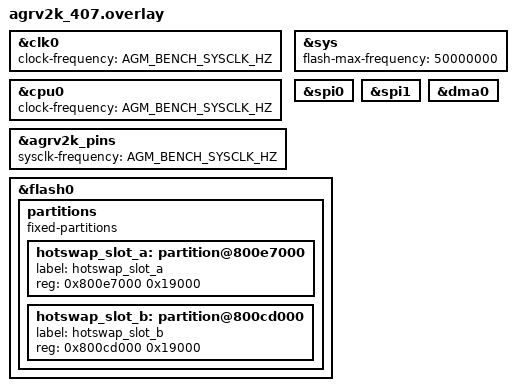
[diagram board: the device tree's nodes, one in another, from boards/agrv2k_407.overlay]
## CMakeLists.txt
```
# SPDX-License-Identifier: Apache-2.0
cmake_minimum_required(VERSION 3.20.0)

find_package(Zephyr REQUIRED HINTS $ENV{ZEPHYR_BASE})
project(fcb_hotswap)

target_sources(app PRIVATE src/main.c src/slot.c)
```

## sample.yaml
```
# SPDX-License-Identifier: Apache-2.0
sample:
  name: fcb_hotswap
  description: |
    Runtime (hot) fabric reload: validate a spare bitstream in FLASH, move the
    CPU onto the on-die HSI clock, run the FCB DEACTIVATE/AUTO/ACTIVATE
    sequence, hand the clock tree to the new fabric and re-assert the pin
    routes — all without a reboot. The SPI NOR RDID probe changes with the
    fabric while k_uptime keeps counting, which is the evidence. Requires two
    same-class bitstreams in FLASH (see README.md).
tests:
  sample.fcb_hotswap.agm_agrv2k_407:
    build_only: true
    platform_allow:
      - agrv2k_407
    integration_platforms:
      - agrv2k_407
    tags:
      - ci_build
      - hal_ag32
```

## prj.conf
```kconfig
# SPDX-License-Identifier: Apache-2.0
CONFIG_SERIAL=y
CONFIG_UART_CONSOLE=y
CONFIG_PRINTK=y
CONFIG_STDOUT_CONSOLE=y
CONFIG_XIP=y

# The fabric-change evidence is a SPI NOR RDID probe: which controller reaches
# the flash, and whether the engine sees MISO at all, is a property of the
# bitstream that is live. Same SPI/DMA set as samples/spi_flash_id.
CONFIG_SPI=y
CONFIG_DMA=y

# The sample re-asserts the console/SPI pin routes after the swap (the new
# bitstream owns AFSEL at ACTIVATE), so pinctrl must be on.
CONFIG_PINCTRL=y

# CPU clock-frequency is a devicetree literal (kernel tick) — nothing to set
# here. No CONFIG_REBOOT: this sample's whole point is *not* rebooting.
```

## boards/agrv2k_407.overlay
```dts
/* SPDX-License-Identifier: Apache-2.0 */
/*
 * fcb_hotswap — 100 MHz SYSCLK overlay.
 *
 * Both dev board bitstreams ($HOME/spi_full_bitstream_97pad/example_board.bin in
 * slot A, $HOME/spi_full_bitstream_without_flash/example_board.bin in slot B)
 * are 100 MHz / HSECLK 8 designs, while the agrv2k_407 dts assumes the 200 MHz
 * vendor image. A hot swap cannot fix a clock-class mismatch: the new fabric
 * *is* the clock, so the console would come back as garbage instead of
 * proving anything. Keep the DT and both bitstreams on the same rate.
 *
 * Same shape as samples/fcb_reload/boards/agrv2k_407.overlay.
 */
#define AGM_BENCH_SYSCLK_HZ 100000000

&clk0 {
	clock-frequency = <AGM_BENCH_SYSCLK_HZ>;
};

&cpu0 {
	clock-frequency = <AGM_BENCH_SYSCLK_HZ>;
};

/* The pin map carries the number the bitstream is rendered from; keep it
 * on the same rate as the firmware clocks above (generate_board_ve.py
 * fails otherwise). */
&agrv2k_pins {
	sysclk-frequency = <AGM_BENCH_SYSCLK_HZ>;
};

/* FLASH ceiling. The 407 board default (100 MHz) makes the SCLK divider 0
 * (SCLK == SYSCLK); the proven dev board pair for these vendor bitstreams is
 * SYSCLK 100 / FLASH ceiling 50 (the same numbers the agrv2k_103 board and
 * the SPI dev boards' /tmp/agm100.overlay use), i.e. divider 1. Keep it explicit
 * here so the sample is reproducible without that out-of-tree file — the
 * hot swap re-derives this value from DT at swap time.
 */
&sys {
	flash-max-frequency = <50000000>;
};

/* The RDID probe reads whichever controller the live fabric routes to the
 * SPI NOR; route both so the probe can report "answers" vs "nothing". */
&spi0 {
	status = "okay";
};

&spi1 {
	status = "okay";
};

/* AHB clock/reset for the SPI engine's DMA support. */
&dma0 {
	status = "okay";
};

/*
 * The two fabric slots this sample juggles, as devicetree partitions, so
 * their addresses are a layout fact instead of a Kconfig knob (2026-09-24).
 *
 * `reg` is the *absolute* address here: on this tree edtlib does not
 * translate fixed-partitions children (the parent flash node has no
 * `ranges`), and the samples that point /chosen/zephyr,code-partition at one
 * of these link at the number written here -- measured with
 * samples/spi_boot_app, whose `reg = <0x8007c000 …>` comes out as
 * CONFIG_FLASH_BASE_ADDRESS = 0x8007c000. So the C side reads DT_REG_ADDR(),
 * not DT_FIXED_PARTITION_ADDR() (that one adds the parent's base again and
 * would answer 0x1000e7000).
 *
 * src/main.c asserts both against the SoC's own constants
 * (AGM_BITSTREAM_FACTORY_ADDR / AGM_BITSTREAM_SLOT2_ADDR): the FCB and the
 * FLASH option byte use those whether or not this devicetree agrees, so a
 * partition that drifted has to fail the build rather than silently write
 * somebody else's region.
 */
&flash0 {
	partitions {
		compatible = "fixed-partitions";
		#address-cells = <1>;
		#size-cells = <1>;

		/* Slot A: the factory slot, what the option byte points at. */
		hotswap_slot_a: partition@800e7000 {
			label = "hotswap_slot_a";
			reg = <0x800e7000 0x19000>;
		};

		/* Slot B: the fabric update slot that is *not* live. */
		hotswap_slot_b: partition@800cd000 {
			label = "hotswap_slot_b";
			reg = <0x800cd000 0x19000>;
		};
	};
};
```

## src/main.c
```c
/*
 * Copyright (c) 2026 AgRV Contributors
 * SPDX-License-Identifier: Apache-2.0
 *
 * fcb_hotswap — reload the FPGA fabric at runtime, without rebooting.
 *
 * Two bitstreams live in FLASH:
 *   slot A (0x800e7000, the boot slot): what the FLASH option byte
 *           "FPGA CONFIG" points at, so it is what the board runs after a
 *           reset — written with tools/flash_logic.sh;
 *   slot B (0x800cd000, the spare):   never booted, written with
 *           tools/agm_oo.sh fw <image.bin> 0x800cd000 (the real fabric
 *           update slot 2; the default was 0x800c0000 until 2026-09-24,
 *           which overlapped fabric slot 1, the bind-salt sector and slot 2
 *           -- see docs/FLASH-LAYOUT.md).
 *
 * Pressing 'x' swaps the live fabric to the other slot:
 *
 *   1. validate the target image (CRC-32/BZIP2 + IDCODE) — a rejected image
 *      must never reach ACTIVATE, because that is the point of no return;
 *   2. agrv2k_clk_switch_hsi() — move the CPU onto the on-die RC clock, the
 *      only clock that does not come out of the fabric;
 *   3. agrv2k_fcb_reload() — DEACTIVATE / stream 24986 words / ACTIVATE;
 *   4. agrv2k_clk_switch_pll() + re-assert pinctrl — hand the clock tree and
 *      the pin routes to the new fabric.
 *
 * Nothing is rebooted, so the evidence is a *pair* of observations:
 *   - the same k_uptime keeps counting and no boot banner appears, while
 *   - the SPI NOR RDID probe changes with the fabric (slot A on this dev board
 *     routes SPI0 to the flash: 68 40 15 W25Q16; slot B routes it nowhere:
 *     00 00 00) — for identical firmware.
 *
 * Constraints (the port record (peripherals) 3.8.3): both images have to be
 * the same clock class and keep the console pin route, and the swap window is
 * several ms in which the console can drop out. If the fabric never comes
 * back, SWD is gone too; the way out is BOOT0 + agrv32flash.
 *
 * Commands: x = swap, i = HSI round trip only, s = probe, q = halt, h = help.
 */

#include <zephyr/kernel.h>
#include <zephyr/device.h>
#include <zephyr/devicetree.h>
#include <zephyr/drivers/misc/agm_bitstream.h>
#include <zephyr/drivers/pinctrl.h>
#include <zephyr/drivers/uart.h>
#include <zephyr/sys/printk.h>
#include <zephyr/sys/sys_io.h>
#include <zephyr/sys/util.h>

#include <errno.h>
#include <stdint.h>

/* soc/agm/agrv2k/{fcb,clk}.c — the same entry points soc.c uses at boot. */
extern int agrv2k_fcb_reload(uint32_t flash_addr);
extern void agrv2k_fcb_log_status(const char *tag);
extern void agrv2k_clk_switch_hsi(void);
extern void agrv2k_clk_switch_pll(uint32_t pll_hz, uint32_t flash_max_hz);

/* src/slot.c */
extern int slot_verify(uint32_t addr, uint32_t *idcode);
extern int slot_rdid(uint8_t out[3]);
extern const char *slot_rdid_name(const uint8_t rdid[3]);

/* Slot addresses come from the devicetree (boards/agrv2k_407.overlay):
 * DT_REG_ADDR() on a fixed-partitions child is the address itself on this
 * tree (see the comment there for why it is not the *_ADDR macro that adds
 * the parent's base). Both are pinned to the addresses the FCB and the FLASH
 * option byte actually use -- a partition that drifted must fail the build,
 * not write into whatever else lives there.
 */
#define SLOT_A_ADDR DT_REG_ADDR(DT_NODELABEL(hotswap_slot_a))
#define SLOT_B_ADDR DT_REG_ADDR(DT_NODELABEL(hotswap_slot_b))

BUILD_ASSERT(SLOT_A_ADDR == (uint32_t)AGM_BITSTREAM_FACTORY_ADDR,
	     "slot A has to be the factory slot the option byte points at");
BUILD_ASSERT(SLOT_B_ADDR == (uint32_t)AGM_BITSTREAM_SLOT2_ADDR,
	     "slot B has to be one of the fabric update slots (slot 2)");

#define SYS_BASE            0x03000000UL
#define SYS_RST_CNTL        0x04UL
#define SYS_APB_CLKENABLE   0x60UL
#define SYS_RST_REMOVE      BIT(24)

/* Same two devicetree values soc.c uses for its clock switch (board dts /
 * overlay), read through the sys node's phandle. */
static const uint32_t pll_hz =
	DT_PROP_BY_PHANDLE(DT_NODELABEL(sys), clocks, clock_frequency);
static const uint32_t flash_max_hz =
	DT_PROP(DT_NODELABEL(sys), flash_max_frequency);

/*
 * Pin routes to re-assert after the fabric changes. The new bitstream owns
 * AFSEL/DIR at ACTIVATE, and both the console and the SPI probe pins have to
 * come back before the sample can report anything. Each device's pinctrl
 * state is defined here (the drivers' own configs are static to their
 * translation units), so this still goes through pinctrl_configure_pins() —
 * nothing in this sample writes AFSEL itself.
 *
 * The nodes are named explicitly rather than derived with
 * DT_FOREACH_STATUS_OKAY: that macro wraps each expansion in COND_CODE_1,
 * which cannot emit declarations (it only works in expression position).
 */
PINCTRL_DT_DEFINE(DT_NODELABEL(uart0));
PINCTRL_DT_DEFINE(DT_NODELABEL(spi0));

#if DT_NODE_HAS_STATUS(DT_NODELABEL(spi1), okay)
PINCTRL_DT_DEFINE(DT_NODELABEL(spi1));
#endif

static const struct pinctrl_dev_config *const pinned[] = {
	PINCTRL_DT_DEV_CONFIG_GET(DT_NODELABEL(uart0)),
	PINCTRL_DT_DEV_CONFIG_GET(DT_NODELABEL(spi0)),
#if DT_NODE_HAS_STATUS(DT_NODELABEL(spi1), okay)
	PINCTRL_DT_DEV_CONFIG_GET(DT_NODELABEL(spi1)),
#endif
};

static uint32_t live_slot = SLOT_A_ADDR;
static uint32_t swap_count;

static const char *slot_desc(int rc)
{
	switch (rc) {
	case 0:
		return "ok";
	case -ENODATA:
		return "empty (erased)";
	case -EILSEQ:
		return "checksum mismatch";
	default:
		return "unreadable";
	}
}

static void report_slots(void)
{
	uint32_t idcode = 0U;
	int rc;

	rc = slot_verify(SLOT_A_ADDR, &idcode);
	printk("hotswap: slot A @0x%08x boot slot  : %s", SLOT_A_ADDR,
	       slot_desc(rc));
	if (rc == 0) {
		printk(" (idcode=0x%08x)", idcode);
	}
	printk("\n");

	rc = slot_verify(SLOT_B_ADDR, &idcode);
	printk("hotswap: slot B @0x%08x spare      : %s", SLOT_B_ADDR,
	       slot_desc(rc));
	if (rc == 0) {
		printk(" (idcode=0x%08x)", idcode);
	}
	printk("\n");
}

/*
 * One line of "what is live right now": FCB verdict, uptime, SYS state and
 * the SPI probe. Called before and after a swap so the two can be diffed.
 */
static void fabric_state(const char *tag)
{
	uint8_t rdid[3] = { 0U, 0U, 0U };
	int rc = slot_rdid(rdid);

	agrv2k_fcb_log_status(tag);
	printk("hotswap [%s]: uptime=%u ms rst=0x%08x apb=0x%08x "
	       "live=0x%08x rdid=%02x %02x %02x (%s)\n",
	       tag, (unsigned int)k_uptime_get_32(),
	       sys_read32(SYS_BASE + SYS_RST_CNTL),
	       sys_read32(SYS_BASE + SYS_APB_CLKENABLE),
	       live_slot, rdid[0], rdid[1], rdid[2],
	       (rc == 0) ? slot_rdid_name(rdid) : "probe failed");
}

static void repin(void)
{
	for (size_t i = 0; i < ARRAY_SIZE(pinned); i++) {
		int rc = pinctrl_apply_state(pinned[i], PINCTRL_STATE_DEFAULT);

		if (rc != 0) {
			printk("hotswap: pinctrl state %u re-apply failed (%d)\n",
			       (unsigned int)i, rc);
		}
	}
}

static void hot_swap(void)
{
	uint32_t dst = (live_slot == SLOT_A_ADDR) ? SLOT_B_ADDR : SLOT_A_ADDR;
	const char *dst_name = (dst == SLOT_B_ADDR) ? "B" : "A";
	uint32_t idcode = 0U;
	uint32_t t0;
	uint32_t n = swap_count + 1U;
	int rc;

	printk("\nhotswap: swap #%u: 0x%08x -> 0x%08x (slot %s)\n",
	       (unsigned int)n, live_slot, dst, dst_name);

	/* Gate first: this is the same check the silicon does at ACTIVATE,
	 * but it costs nothing to fail here. */
	rc = slot_verify(dst, &idcode);
	if (rc != 0) {
		printk("hotswap: slot %s rejected (%s) — fabric untouched, "
		       "still on 0x%08x\n", dst_name, slot_desc(rc), live_slot);
		return;
	}
	printk("hotswap: slot %s verified (idcode=0x%08x, crc ok)\n",
	       dst_name, idcode);

	/* Everything up to the clock switch back runs with the console
	 * expected to drop out: the pins it prints through belong to the
	 * fabric being replaced. No printk in the window. */
	printk("hotswap: sys_clk -> HSI (CPU off the fabric clock)\n");
	t0 = k_uptime_get_32();
	agrv2k_clk_switch_hsi();

	rc = agrv2k_fcb_reload(dst);

	agrv2k_clk_switch_pll(pll_hz, flash_max_hz);
	repin();

	if (rc == 0) {
		live_slot = dst;
		swap_count = n;
	}
	printk("\nhotswap: FCB reload %s (rc=%d), window %u ms\n",
	       (rc == 0) ? "completed" : "FAILED", rc,
	       (unsigned int)(k_uptime_get_32() - t0));

	fabric_state("post");
	if (rc == 0) {
		printk("hotswap: slot %s is live; uptime kept counting and no "
		       "boot banner appeared, so the core was never reset — "
		       "that is the hot swap\n", dst_name);
	}
}

/*
 * HSI round trip with no fabric change: isolates "can this core run off a
 * clock that does not come from the fabric?" from everything else. If the
 * console stays alive here but dies in 'x', the DEACTIVATE is the culprit.
 */
static void hsi_roundtrip(void)
{
	uint32_t t0 = k_uptime_get_32();

	printk("\nhotswap: HSI round trip (no fabric change)\n");
	agrv2k_clk_switch_hsi();
	printk("hotswap: on HSI, still executing (uptime=%u ms, %u ms since "
	       "the request)\n", (unsigned int)k_uptime_get_32(),
	       (unsigned int)(k_uptime_get_32() - t0));
	k_msleep(10);
	printk("hotswap: alive after a 10 ms sleep on HSI (uptime=%u ms)\n",
	       (unsigned int)k_uptime_get_32());
	agrv2k_clk_switch_pll(pll_hz, flash_max_hz);
	printk("hotswap: back on the fabric PLL (uptime=%u ms)\n",
	       (unsigned int)k_uptime_get_32());
}

static void cmd_help(void)
{
	printk("hotswap commands:\n");
	printk("  x  hot swap to the other slot (validated first)\n");
	printk("  i  HSI round trip only — no fabric change\n");
	printk("  s  probe: FCB STAT + SPI RDID + both slot verdicts\n");
	printk("  q  halt here — SWD attach point\n");
	printk("  h  this menu\n");
}

static void handle_cmd(char c)
{
	switch (c) {
	case 'x':
	case 'X':
		hot_swap();
		break;
	case 'i':
	case 'I':
		hsi_roundtrip();
		break;
	case 's':
	case 'S':
		report_slots();
		fabric_state("s");
		break;
	case 'q':
	case 'Q':
		printk("hotswap: halted — SWD may attach\n");
		for (;;) {
			k_msleep(1000);
		}
	case 'h':
	case 'H':
	case '?':
		cmd_help();
		break;
	case '\r':
	case '\n':
		break;
	default:
		printk("? '%c' (press h for help)\n", c);
		break;
	}
}

int main(void)
{
	const struct device *uart = DEVICE_DT_GET(DT_CHOSEN(zephyr_console));
	uint32_t rst;
	char c;

	if (!device_is_ready(uart)) {
		for (;;) {
			k_msleep(1000);
		}
	}

	rst = sys_read32(SYS_BASE + SYS_RST_CNTL);
	printk("\n=== fcb_hotswap: runtime fabric reload (no reboot) ===\n");
	printk("hotswap: sys pll=%u Hz flash_max=%u Hz rst=0x%08x apb=0x%08x\n",
	       (unsigned int)pll_hz, (unsigned int)flash_max_hz, rst,
	       sys_read32(SYS_BASE + SYS_APB_CLKENABLE));
	/* Clear the sticky reset flags so the next run starts clean. */
	sys_write32(rst | SYS_RST_REMOVE, SYS_BASE + SYS_RST_CNTL);

	report_slots();
	fabric_state("boot");
	cmd_help();
	printk("hotswap> ");

	for (;;) {
		if (uart_poll_in(uart, &c) == 0) {
			handle_cmd(c);
			printk("hotswap> ");
		}
		k_msleep(10);
	}
}
```

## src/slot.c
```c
/*
 * Copyright (c) 2026 AgRV Contributors
 * SPDX-License-Identifier: Apache-2.0
 *
 * Slot validation + the "which fabric is live" probe for fcb_hotswap.
 *
 * Why validating first matters: the FCB only checks the image *at ACTIVATE*,
 * i.e. at the exact moment the running fabric is already gone. A rejected
 * image therefore leaves the board in the state
 * the port record (peripherals) 3.8.1 describes (core stopped, console
 * dead, SWD AP stalled) with BOOT0 + agrv32flash as the only way back. The
 * bitstream carries its own checksum, so the same check can run *before*
 * anything is touched.
 *
 * Checksum format (measured 2026-09-14 against <build_dir>/zephyr/board.bin,
 * ~/spi_full_bitstream_97pad/example_board.bin and
 * ~/spi_full_bitstream_without_flash/example_board.bin):
 *
 *   image  = 24986 words (99944 bytes, FCB_AUTO_WORDS from the vendor SDK)
 *   word 0 = 0x01002040 (IDCODE), word 1 = 0xffff0000 (USERID)
 *   CRC    = CRC-32/BZIP2 (poly 0x04C11DB7, init 0xFFFFFFFF, no bit
 *            reflection, final xor 0xFFFFFFFF) over bytes 0..99939,
 *            stored big-endian in the last four bytes.
 *
 * All three images satisfy it — including the two that differ in 3137 words —
 * so this is not a constant that happens to match one file.
 */

#include <errno.h>
#include <stdbool.h>
#include <stddef.h>
#include <stdint.h>

#include <zephyr/device.h>
#include <zephyr/devicetree.h>
#include <zephyr/drivers/spi.h>
#include <zephyr/sys/printk.h>
#include <zephyr/sys/util.h>

#if !defined(CONFIG_LITTLE_ENDIAN)
#error "fcb_hotswap: the slot CRC walks image words as little-endian bytes"
#endif

#if !DT_HAS_COMPAT_STATUS_OKAY(agm_agrv2k_spi)
#error "fcb_hotswap: need agm,agrv2k-spi enabled in the build"
#endif

/* Mirrors FCB_AUTO_WORDS in soc/agm/agrv2k/fcb.c (vendor SDK
 * fcb.h:FCB_AUTO_WORDS = 99944/4). */
#define SLOT_WORDS      24986U

#define CRC32_BZIP2_POLY 0x04C11DB7U

static uint32_t crc32_table[256];
static bool crc32_table_ready;

static uint32_t crc32_update(uint32_t crc, uint8_t byte)
{
	return (crc << 8) ^ crc32_table[((crc >> 24) ^ byte) & 0xFFU];
}

static void crc32_table_build(void)
{
	for (uint32_t i = 0; i < 256U; i++) {
		uint32_t c = i << 24;

		for (int bit = 0; bit < 8; bit++) {
			c = ((c & 0x80000000U) != 0U)
				    ? ((c << 1) ^ CRC32_BZIP2_POLY)
				    : (c << 1);
		}
		crc32_table[i] = c;
	}
	crc32_table_ready = true;
}

/*
 * Returns 0 if the slot at `addr` holds a bitstream the FCB would accept, and
 * leaves its IDCODE (image word 0) in *idcode when the pointer is not NULL.
 *
 *   -ENODATA  empty slot (erased 0xFF, or 0x00): nothing written there yet
 *   -EILSEQ   checksum mismatch: truncated or half-written image
 */
int slot_verify(uint32_t addr, uint32_t *idcode)
{
	const volatile uint32_t *img = (const volatile uint32_t *)addr;
	uint32_t crc;
	uint32_t stored;
	uint32_t first = img[0];

	if ((first == 0xFFFFFFFFU) && (img[1] == 0xFFFFFFFFU) &&
	    (img[2] == 0xFFFFFFFFU) && (img[3] == 0xFFFFFFFFU)) {
		return -ENODATA;
	}
	if ((first == 0U) && (img[1] == 0U) && (img[2] == 0U) &&
	    (img[3] == 0U)) {
		return -ENODATA;
	}

	if (!crc32_table_ready) {
		crc32_table_build();
	}

	crc = 0xFFFFFFFFU;
	for (uint32_t i = 0; i < (SLOT_WORDS - 1U); i++) {
		uint32_t word = img[i];

		for (int b = 0; b < 4; b++) {
			crc = crc32_update(crc, (uint8_t)(word >> (8 * b)));
		}
	}
	crc ^= 0xFFFFFFFFU;

	/* Stored big-endian: 0x9eae7287 lives at the end of example_board.bin
	 * as 9e ae 72 87. */
	stored = (img[SLOT_WORDS - 1U] & 0xFFU) << 24;
	stored |= ((img[SLOT_WORDS - 1U] >> 8) & 0xFFU) << 16;
	stored |= ((img[SLOT_WORDS - 1U] >> 16) & 0xFFU) << 8;
	stored |= (img[SLOT_WORDS - 1U] >> 24) & 0xFFU;

	if (crc != stored) {
		return -EILSEQ;
	}
	if (idcode != NULL) {
		*idcode = first;
	}
	return 0;
}

/*
 * SPI NOR RDID probe (0x9F, 3-byte response). Same shape as
 * samples/fcb_reload's spi_id.c: a transfer starts with TX, RX is the last
 * segment, and the driver's TX-then-RX cycle hides the command byte as 0xFF
 * in the first RX slot. Which controller reaches the flash is a property of
 * the live bitstream, so probe every enabled one and report the first that
 * answers.
 */
#define HOTSWAP_SPI_ENTRY(node) DEVICE_DT_GET(node),

static const struct device *const spi_controllers[] = {
	DT_FOREACH_STATUS_OKAY(agm_agrv2k_spi, HOTSWAP_SPI_ENTRY)
};

static const struct spi_config spi_cfg = {
	.frequency = 1000000U, /* 1 MHz — conservative, the fabric is unknown */
	.operation = SPI_OP_MODE_CONTROLLER | SPI_WORD_SET(8) | SPI_TRANSFER_MSB,
	.slave = 0,
	.cs = { .cs_is_gpio = false },
};

static int rdid_once(const struct device *spi, uint8_t out[3])
{
	uint8_t cmd = 0x9FU; /* RDID */
	uint8_t echo;
	uint8_t rx[3] = { 0 };
	struct spi_buf tx_buf = { .buf = &cmd, .len = 1U };
	struct spi_buf rx_bufs[2] = {
		{ .buf = &echo, .len = 1U },
		{ .buf = rx, .len = 3U },
	};
	const struct spi_buf_set tx_set = { .buffers = &tx_buf, .count = 1U };
	const struct spi_buf_set rx_set = { .buffers = rx_bufs, .count = 2U };

	int ret = spi_transceive(spi, &spi_cfg, &tx_set, &rx_set);

	if (ret < 0) {
		return ret;
	}
	out[0] = rx[0];
	out[1] = rx[1];
	out[2] = rx[2];
	return 0;
}

int slot_rdid(uint8_t out[3])
{
	bool have_blank = false;
	uint8_t blank[3] = { 0 };

	for (size_t i = 0; i < ARRAY_SIZE(spi_controllers); i++) {
		const struct device *spi = spi_controllers[i];
		uint8_t r[3] = { 0 };

		if (!device_is_ready(spi)) {
			continue;
		}
		if (rdid_once(spi, r) < 0) {
			printk("hotswap: %s RDID read failed\n", spi->name);
			continue;
		}
		printk("hotswap: %s RDID = %02x %02x %02x\n",
		       spi->name, r[0], r[1], r[2]);

		if (!((r[0] == 0U && r[1] == 0U && r[2] == 0U) ||
		      (r[0] == 0xFFU && r[1] == 0xFFU && r[2] == 0xFFU))) {
			out[0] = r[0];
			out[1] = r[1];
			out[2] = r[2];
			return 0;
		}
		if (!have_blank) {
			blank[0] = r[0];
			blank[1] = r[1];
			blank[2] = r[2];
			have_blank = true;
		}
	}

	if (!have_blank) {
		return -ENODEV;
	}
	out[0] = blank[0];
	out[1] = blank[1];
	out[2] = blank[2];
	return 0;
}

const char *slot_rdid_name(const uint8_t rdid[3])
{
	if (rdid[0] == 0xC8U && rdid[1] == 0x40U && rdid[2] == 0x16U) {
		return "GD25Qxx";
	}
	if (rdid[0] == 0x68U && rdid[1] == 0x40U && rdid[2] == 0x15U) {
		return "W25Q16";
	}
	if (rdid[0] == 0x00U && rdid[1] == 0x00U && rdid[2] == 0x00U) {
		return "nothing answering (MISO held low)";
	}
	if (rdid[0] == 0xFFU && rdid[1] == 0xFFU && rdid[2] == 0xFFU) {
		return "nothing answering (MISO floating high)";
	}
	return "unexpected";
}
```
